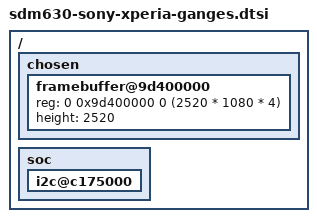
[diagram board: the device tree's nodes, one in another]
// SPDX-License-Identifier: BSD-3-Clause
/*
 * Copyright (c) 2020, Martin Botka
 */

/dts-v1/;

/* Ganges is very similar to Nile, but
 * there are some differences that will need
 * to be addresed when more peripherals are
 * enabled upstream. Hence the separate DTSI.
 */
#include "sdm630-sony-xperia-nile.dtsi"

/ {
	chosen {
		framebuffer@9d400000 {
			reg = <0 0x9d400000 0 (2520 * 1080 * 4)>;
			height = <2520>;
		};
	};

	/* Yes, this is intentional.
	 * Ganges devices only use gpio-keys for
	 * Volume Down, but currently there's an
	 * issue with it that has to be resolved.
	 * Until then, let's not make the kernel panic
	 */
	/delete-node/ gpio-keys;

	soc {

		i2c@c175000 {
			status = "okay";

			/* Novatek touchscreen */
		};
	};

};
